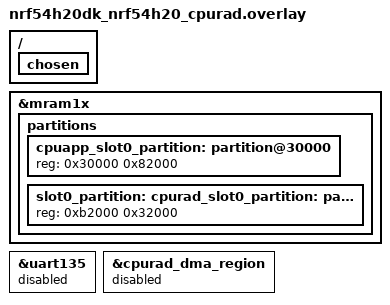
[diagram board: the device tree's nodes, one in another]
/*
 * Copyright (c) 2024 Nordic Semiconductor ASA
 *
 * SPDX-License-Identifier: LicenseRef-Nordic-5-Clause
 */

/ {
	chosen {
		/delete-property/ zephyr,console;
		/delete-property/ zephyr,shell-uart;
	};
};

/delete-node/ &cpuapp_slot0_partition;
/delete-node/ &cpurad_slot0_partition;

&mram1x {
	partitions {
		cpuapp_slot0_partition: partition@30000 {
			reg = <0x30000 0x82000>;
		};

		slot0_partition: cpurad_slot0_partition: partition@b2000 {
			reg = <0xb2000 0x32000>;
		};
	};
};

&uart135 {
	status = "disabled";
};

&cpurad_dma_region {
	status = "disabled";
};
